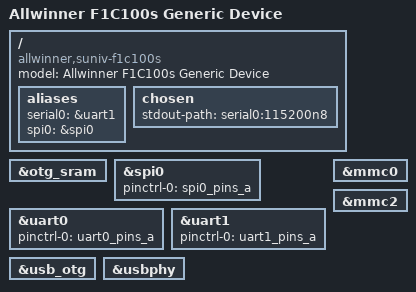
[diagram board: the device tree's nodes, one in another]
// SPDX-License-Identifier: (GPL-2.0+ OR X11)

/dts-v1/;
#include "suniv-f1c100s.dtsi"

#include <dt-bindings/gpio/gpio.h>

/ {
	model = "Allwinner F1C100s Generic Device";
	compatible = "allwinner,suniv-f1c100s",
		     "allwinner,suniv";

	aliases {
		serial0 = &uart1;
		spi0 = &spi0;
	};

	chosen {
		stdout-path = "serial0:115200n8";
	};
};

&otg_sram {
	status = "okay";
};

&spi0 {
	pinctrl-names = "default";
	pinctrl-0 = <&spi0_pins_a>;
	status = "okay";
};

&uart0 {
	pinctrl-names = "default";
	pinctrl-0 = <&uart0_pins_a>;
	status = "okay";
};

&uart1 {
	pinctrl-names = "default";
	pinctrl-0 = <&uart1_pins_a>;
	status = "okay";
};

&usb_otg {
	status = "okay";
};

&usbphy {
	status = "okay";
};

&mmc0 {
	status = "okay";
};

&mmc2 {
	status = "okay";
};
